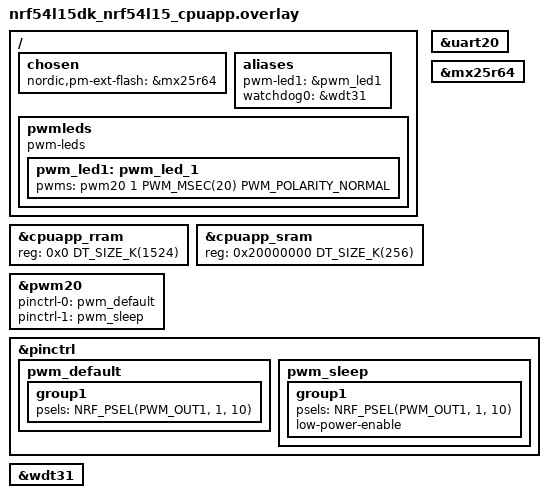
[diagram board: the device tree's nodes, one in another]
/*
 *    Copyright (c) 2025 Project CHIP Authors
 *
 *    Licensed under the Apache License, Version 2.0 (the "License");
 *    you may not use this file except in compliance with the License.
 *    You may obtain a copy of the License at
 *
 *        http://www.apache.org/licenses/LICENSE-2.0
 *
 *    Unless required by applicable law or agreed to in writing, software
 *    distributed under the License is distributed on an "AS IS" BASIS,
 *    WITHOUT WARRANTIES OR CONDITIONS OF ANY KIND, either express or implied.
 *    See the License for the specific language governing permissions and
 *    limitations under the License.
 */

/ {
	chosen {
		nordic,pm-ext-flash = &mx25r64;
	};

	aliases {
		// Configure PWM module for led1 (LED2 on the board)
		pwm-led1 = &pwm_led1;

		// Use watchdog wdt31 as the application watchdog
		watchdog0 = &wdt31;
	};

	pwmleds {
		compatible = "pwm-leds";
		pwm_led1: pwm_led_1 {
			pwms = <&pwm20 1 PWM_MSEC(20) PWM_POLARITY_NORMAL>;
		};
	};
};

// restore full RRAM and SRAM space - by default some parts are dedicated to FLRP
&cpuapp_rram {
	reg = <0x0 DT_SIZE_K(1524)>;
};

&cpuapp_sram {
	reg = <0x20000000 DT_SIZE_K(256)>;
	ranges = <0x0 0x20000000 0x40000>;
};

// TODO: re-enable HWFC once it's fixed
&uart20 {
	/delete-property/ hw-flow-control;
};

&mx25r64 {
	status = "okay";
};

&pwm20 {
	status = "okay";
	pinctrl-0 = <&pwm_default>;
	pinctrl-1 = <&pwm_sleep>;
	pinctrl-names = "default", "sleep";
};

&pinctrl {
	pwm_default: pwm_default {
		group1 {
			psels = <NRF_PSEL(PWM_OUT1, 1, 10)>;
		};
	};
	pwm_sleep: pwm_sleep {
		group1 {
			psels = <NRF_PSEL(PWM_OUT1, 1, 10)>;
			low-power-enable;
		};
	};
};

&wdt31 {
	status = "okay";
};
